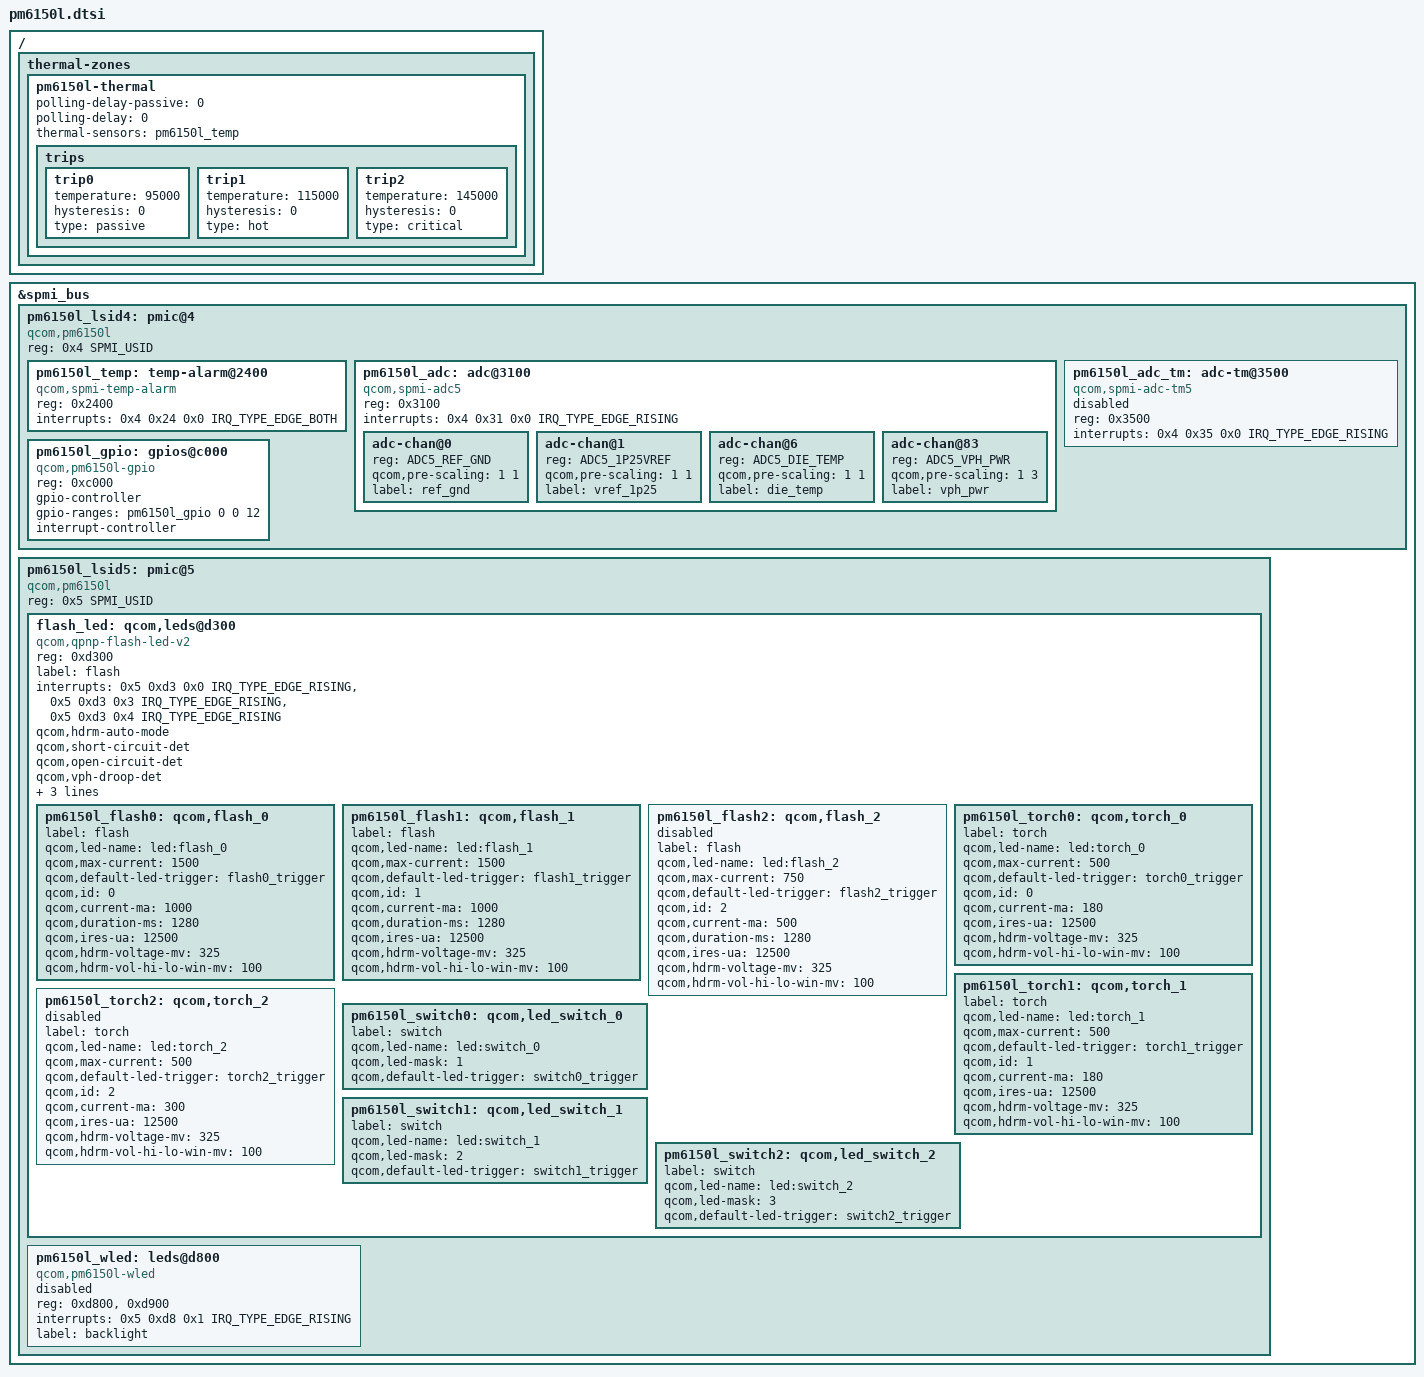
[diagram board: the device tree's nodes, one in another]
// SPDX-License-Identifier: BSD-3-Clause
// Copyright (c) 2019, The Linux Foundation. All rights reserved.

#include <dt-bindings/iio/qcom,spmi-vadc.h>
#include <dt-bindings/interrupt-controller/irq.h>
#include <dt-bindings/spmi/spmi.h>

/ {
	thermal-zones {
		pm6150l-thermal {
			polling-delay-passive = <0>;
			polling-delay = <0>;

			thermal-sensors = <&pm6150l_temp>;

			trips {
				trip0 {
					temperature = <95000>;
					hysteresis = <0>;
					type = "passive";
				};

				trip1 {
					temperature = <115000>;
					hysteresis = <0>;
					type = "hot";
				};

				trip2 {
					temperature = <145000>;
					hysteresis = <0>;
					type = "critical";
				};
			};
		};
	};
};

&spmi_bus {
	pm6150l_lsid4: pmic@4 {
		compatible = "qcom,pm6150l", "qcom,spmi-pmic";
		reg = <0x4 SPMI_USID>;
		#address-cells = <1>;
		#size-cells = <0>;

		pm6150l_temp: temp-alarm@2400 {
			compatible = "qcom,spmi-temp-alarm";
			reg = <0x2400>;
			interrupts = <0x4 0x24 0x0 IRQ_TYPE_EDGE_BOTH>;
			#thermal-sensor-cells = <0>;
		};

		pm6150l_adc: adc@3100 {
			compatible = "qcom,spmi-adc5";
			reg = <0x3100>;
			interrupts = <0x4 0x31 0x0 IRQ_TYPE_EDGE_RISING>;
			#address-cells = <1>;
			#size-cells = <0>;
			#io-channel-cells = <1>;

			adc-chan@0 {
				reg = <ADC5_REF_GND>;
				qcom,pre-scaling = <1 1>;
				label = "ref_gnd";
			};

			adc-chan@1 {
				reg = <ADC5_1P25VREF>;
				qcom,pre-scaling = <1 1>;
				label = "vref_1p25";
			};

			adc-chan@6 {
				reg = <ADC5_DIE_TEMP>;
				qcom,pre-scaling = <1 1>;
				label = "die_temp";
			};

			adc-chan@83 {
				reg = <ADC5_VPH_PWR>;
				qcom,pre-scaling = <1 3>;
				label = "vph_pwr";
			};
		};

		pm6150l_adc_tm: adc-tm@3500 {
			compatible = "qcom,spmi-adc-tm5";
			reg = <0x3500>;
			interrupts = <0x4 0x35 0x0 IRQ_TYPE_EDGE_RISING>;
			#thermal-sensor-cells = <1>;
			#address-cells = <1>;
			#size-cells = <0>;
			status = "disabled";
		};

		pm6150l_gpio: gpios@c000 {
			compatible = "qcom,pm6150l-gpio", "qcom,spmi-gpio";
			reg = <0xc000>;
			gpio-controller;
			gpio-ranges = <&pm6150l_gpio 0 0 12>;
			#gpio-cells = <2>;
			interrupt-controller;
			#interrupt-cells = <2>;
		};
	};

	pm6150l_lsid5: pmic@5 {
		compatible = "qcom,pm6150l", "qcom,spmi-pmic";
		reg = <0x5 SPMI_USID>;
		#address-cells = <1>;
		#size-cells = <0>;

		flash_led: qcom,leds@d300 {
			compatible = "qcom,qpnp-flash-led-v2";
			status = "okay";
			reg = <0xd300>;
			label = "flash";
			interrupts = <0x5 0xd3 0x0 IRQ_TYPE_EDGE_RISING>,
				     <0x5 0xd3 0x3 IRQ_TYPE_EDGE_RISING>,
				     <0x5 0xd3 0x4 IRQ_TYPE_EDGE_RISING>;
			interrupt-names = "led-fault-irq",
					  "all-ramp-down-done-irq",
					  "all-ramp-up-done-irq";
			qcom,hdrm-auto-mode;
			qcom,short-circuit-det;
			qcom,open-circuit-det;
			qcom,vph-droop-det;
			qcom,thermal-derate-en;
			qcom,thermal-derate-current = <200 500 1000>;
			qcom,isc-delay = <192>;
			// qcom,pmic-revid = <&pm6150l_revid>;

			pm6150l_flash0: qcom,flash_0 {
				label = "flash";
				qcom,led-name = "led:flash_0";
				qcom,max-current = <1500>;
				qcom,default-led-trigger = "flash0_trigger";
				qcom,id = <0>;
				qcom,current-ma = <1000>;
				qcom,duration-ms = <1280>;
				qcom,ires-ua = <12500>;
				qcom,hdrm-voltage-mv = <325>;
				qcom,hdrm-vol-hi-lo-win-mv = <100>;
			};

			pm6150l_flash1: qcom,flash_1 {
				label = "flash";
				qcom,led-name = "led:flash_1";
				qcom,max-current = <1500>;
				qcom,default-led-trigger = "flash1_trigger";
				qcom,id = <1>;
				qcom,current-ma = <1000>;
				qcom,duration-ms = <1280>;
				qcom,ires-ua = <12500>;
				qcom,hdrm-voltage-mv = <325>;
				qcom,hdrm-vol-hi-lo-win-mv = <100>;
			};

			pm6150l_flash2: qcom,flash_2 {
				label = "flash";
				qcom,led-name = "led:flash_2";
				qcom,max-current = <750>;
				qcom,default-led-trigger = "flash2_trigger";
				qcom,id = <2>;
				qcom,current-ma = <500>;
				qcom,duration-ms = <1280>;
				qcom,ires-ua = <12500>;
				qcom,hdrm-voltage-mv = <325>;
				qcom,hdrm-vol-hi-lo-win-mv = <100>;
				status = "disabled";
			};

			pm6150l_torch0: qcom,torch_0 {
				label = "torch";
				qcom,led-name = "led:torch_0";
				qcom,max-current = <500>;
				qcom,default-led-trigger = "torch0_trigger";
				qcom,id = <0>;
				qcom,current-ma = <180>;
				qcom,ires-ua = <12500>;
				qcom,hdrm-voltage-mv = <325>;
				qcom,hdrm-vol-hi-lo-win-mv = <100>;
			};

			pm6150l_torch1: qcom,torch_1 {
				label = "torch";
				qcom,led-name = "led:torch_1";
				qcom,max-current = <500>;
				qcom,default-led-trigger = "torch1_trigger";
				qcom,id = <1>;
				qcom,current-ma = <180>;
				qcom,ires-ua = <12500>;
				qcom,hdrm-voltage-mv = <325>;
				qcom,hdrm-vol-hi-lo-win-mv = <100>;
			};

			pm6150l_torch2: qcom,torch_2 {
				label = "torch";
				qcom,led-name = "led:torch_2";
				qcom,max-current = <500>;
				qcom,default-led-trigger = "torch2_trigger";
				qcom,id = <2>;
				qcom,current-ma = <300>;
				qcom,ires-ua = <12500>;
				qcom,hdrm-voltage-mv = <325>;
				qcom,hdrm-vol-hi-lo-win-mv = <100>;
				status = "disabled";
			};

			pm6150l_switch0: qcom,led_switch_0 {
				label = "switch";
				qcom,led-name = "led:switch_0";
				qcom,led-mask = <1>;
				qcom,default-led-trigger = "switch0_trigger";
			};

			pm6150l_switch1: qcom,led_switch_1 {
				label = "switch";
				qcom,led-name = "led:switch_1";
				qcom,led-mask = <2>;
				qcom,default-led-trigger = "switch1_trigger";
			};

			pm6150l_switch2: qcom,led_switch_2 {
				label = "switch";
				qcom,led-name = "led:switch_2";
				qcom,led-mask = <3>;
				qcom,default-led-trigger = "switch2_trigger";
			};
		};

		pm6150l_wled: leds@d800 {
			compatible = "qcom,pm6150l-wled";
			reg = <0xd800>, <0xd900>;
			interrupts = <0x5 0xd8 0x1 IRQ_TYPE_EDGE_RISING>;
			interrupt-names = "ovp";
			label = "backlight";

			status = "disabled";
		};
	};
};
